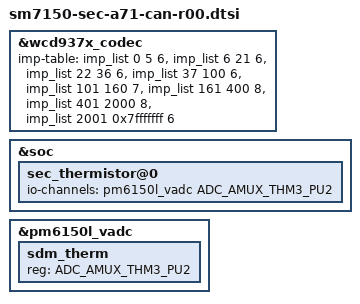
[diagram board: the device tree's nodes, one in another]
/* Copyright (c) 2019, The Linux Foundation. All rights reserved.
 *
 * This program is free software; you can redistribute it and/or modify
 * it under the terms of the GNU General Public License version 2 and
 * only version 2 as published by the Free Software Foundation.
 *
 * This program is distributed in the hope that it will be useful,
 * but WITHOUT ANY WARRANTY; without even the implied warranty of
 * MERCHANTABILITY or FITNESS FOR A PARTICULAR PURPOSE.  See the
 * GNU General Public License for more details.
 */

#include "sm7150-sec-a71-can-pinctrl-r00.dtsi"

#include "../common/sm7150-sec-a71-common.dtsi"
// #include "sm6150-sec-a70q-input-common.dtsi"
#include "../common/sm7150-sec-a71-pm-common.dtsi"
#include "sm7150-sec-a71-battery-can-r00.dtsi"
#include "../drivers/sm7150-sec-a71-eif-common.dtsi"
#include "../drivers/sm7150-sec-a71-fingerprint_00.dtsi"
#include "../drivers/sm7150-sec-a71-nfc-r00.dtsi"
#include "../drivers/sm7150-camera-sensor-a71-r01.dtsi"
//#include "../drivers/sm7150-sec-a71-display-r00.dtsi"

&wcd937x_codec {
	imp-table = <&imp_list 0 5 6>,
			 <&imp_list 6 21 6>,
			 <&imp_list 22 36 6>,
			 <&imp_list 37 100 6>,
			 <&imp_list 101 160 7>,
			 <&imp_list 161 400 8>,
			 <&imp_list 401 2000 8>,
			 <&imp_list 2001 0x7fffffff 6>;
};

&soc {
	sec_thermistor@0 {
		io-channels = <&pm6150l_vadc ADC_AMUX_THM3_PU2>;
	};
};

&pm6150l_vadc {
	sdm_therm {
		reg = <ADC_AMUX_THM3_PU2>;
	};
};
